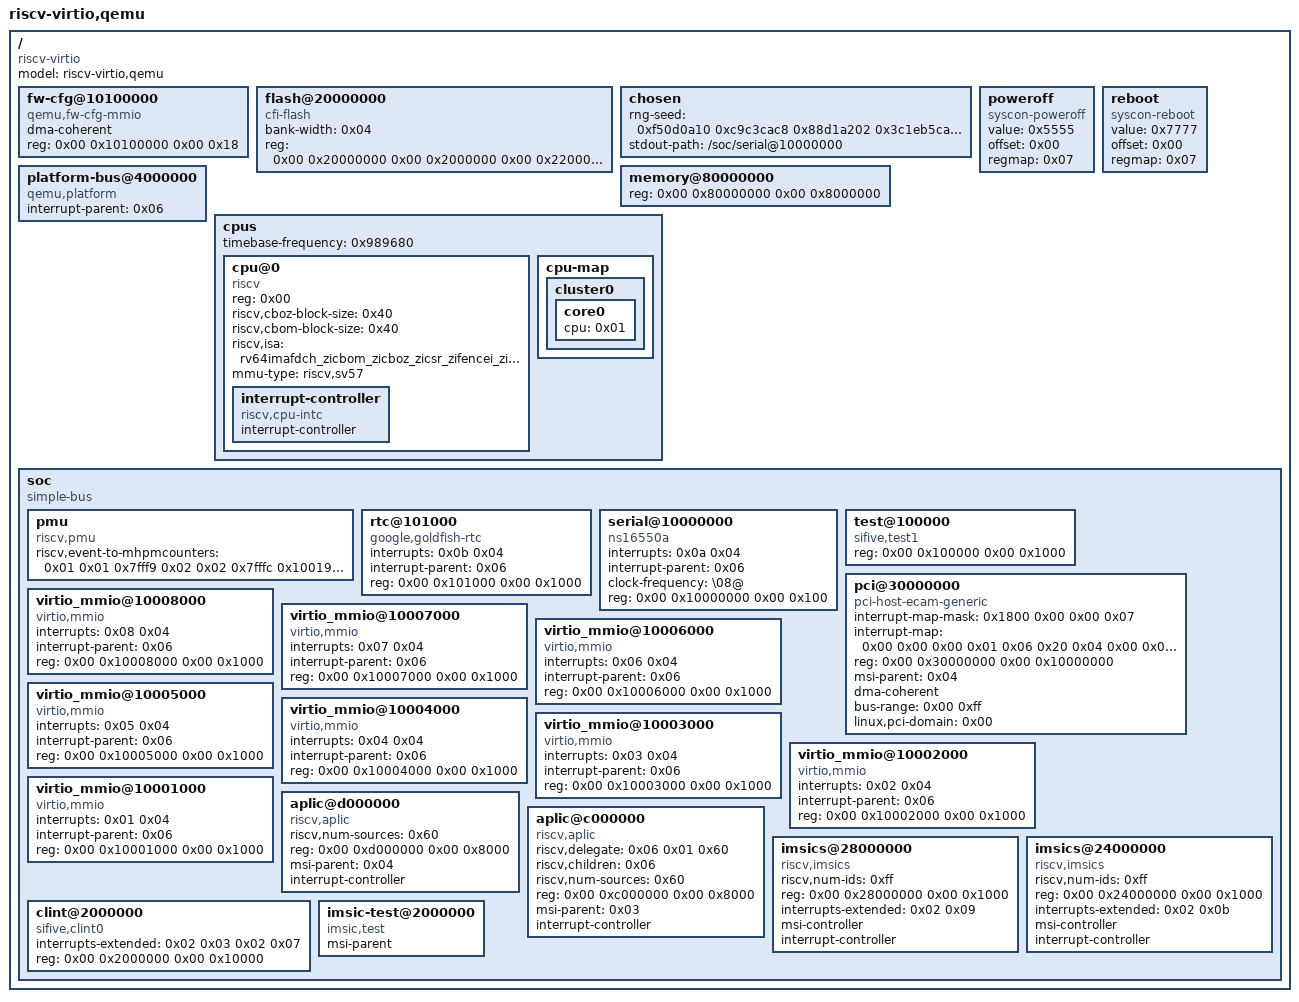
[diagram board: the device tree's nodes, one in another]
/dts-v1/;

/ {
	#address-cells = <0x02>;
	#size-cells = <0x02>;
	compatible = "riscv-virtio";
	model = "riscv-virtio,qemu";

	fw-cfg@10100000 {
		dma-coherent;
		reg = <0x00 0x10100000 0x00 0x18>;
		compatible = "qemu,fw-cfg-mmio";
	};

	flash@20000000 {
		bank-width = <0x04>;
		reg = <0x00 0x20000000 0x00 0x2000000 0x00 0x22000000 0x00 0x2000000>;
		compatible = "cfi-flash";
	};

	chosen {
		rng-seed = <0xf50d0a10 0xc9c3cac8 0x88d1a202 0x3c1eb5ca 0x6d25b5b9 0x8b1cad55 0xbd0cc887 0x8aa1972>;
		stdout-path = "/soc/serial@10000000";
	};

	poweroff {
		value = <0x5555>;
		offset = <0x00>;
		regmap = <0x07>;
		compatible = "syscon-poweroff";
	};

	reboot {
		value = <0x7777>;
		offset = <0x00>;
		regmap = <0x07>;
		compatible = "syscon-reboot";
	};

	platform-bus@4000000 {
		interrupt-parent = <0x06>;
		ranges = <0x00 0x00 0x4000000 0x2000000>;
		#address-cells = <0x01>;
		#size-cells = <0x01>;
		compatible = "qemu,platform\0simple-bus";
	};

	memory@80000000 {
		device_type = "memory";
		reg = <0x00 0x80000000 0x00 0x8000000>;
	};

	cpus {
		#address-cells = <0x01>;
		#size-cells = <0x00>;
		timebase-frequency = <0x989680>;

		cpu@0 {
			phandle = <0x01>;
			device_type = "cpu";
			reg = <0x00>;
			status = "okay";
			compatible = "riscv";
			riscv,cboz-block-size = <0x40>;
			riscv,cbom-block-size = <0x40>;
			riscv,isa = "rv64imafdch_zicbom_zicboz_zicsr_zifencei_zihintpause_zawrs_zfa_zca_zcd_zba_zbb_zbc_zbs_smaia_ssaia_sstc_svadu";
			mmu-type = "riscv,sv57";

			interrupt-controller {
				#interrupt-cells = <0x01>;
				interrupt-controller;
				compatible = "riscv,cpu-intc";
				phandle = <0x02>;
			};
		};

		cpu-map {

			cluster0 {

				core0 {
					cpu = <0x01>;
				};
			};
		};
	};

	soc {
		#address-cells = <0x02>;
		#size-cells = <0x02>;
		compatible = "simple-bus";
		ranges;

		pmu {
			riscv,event-to-mhpmcounters = <0x01 0x01 0x7fff9 0x02 0x02 0x7fffc 0x10019 0x10019 0x7fff8 0x1001b 0x1001b 0x7fff8 0x10021 0x10021 0x7fff8>;
			compatible = "riscv,pmu";
		};

		rtc@101000 {
			interrupts = <0x0b 0x04>;
			interrupt-parent = <0x06>;
			reg = <0x00 0x101000 0x00 0x1000>;
			compatible = "google,goldfish-rtc";
		};

		serial@10000000 {
			interrupts = <0x0a 0x04>;
			interrupt-parent = <0x06>;
			clock-frequency = "\08@";
			reg = <0x00 0x10000000 0x00 0x100>;
			compatible = "ns16550a";
		};

		test@100000 {
			phandle = <0x07>;
			reg = <0x00 0x100000 0x00 0x1000>;
			compatible = "sifive,test1\0sifive,test0\0syscon";
		};

		pci@30000000 {
			interrupt-map-mask = <0x1800 0x00 0x00 0x07>;
			interrupt-map = <0x00 0x00 0x00 0x01 0x06 0x20 0x04 0x00 0x00 0x00 0x02 0x06 0x21 0x04 0x00 0x00 0x00 0x03 0x06 0x22 0x04 0x00 0x00 0x00 0x04 0x06 0x23 0x04 0x800 0x00 0x00 0x01 0x06 0x21 0x04 0x800 0x00 0x00 0x02 0x06 0x22 0x04 0x800 0x00 0x00 0x03 0x06 0x23 0x04 0x800 0x00 0x00 0x04 0x06 0x20 0x04 0x1000 0x00 0x00 0x01 0x06 0x22 0x04 0x1000 0x00 0x00 0x02 0x06 0x23 0x04 0x1000 0x00 0x00 0x03 0x06 0x20 0x04 0x1000 0x00 0x00 0x04 0x06 0x21 0x04 0x1800 0x00 0x00 0x01 0x06 0x23 0x04 0x1800 0x00 0x00 0x02 0x06 0x20 0x04 0x1800 0x00 0x00 0x03 0x06 0x21 0x04 0x1800 0x00 0x00 0x04 0x06 0x22 0x04>;
			ranges = <0x1000000 0x00 0x00 0x00 0x3000000 0x00 0x10000 0x2000000 0x00 0x40000000 0x00 0x40000000 0x00 0x40000000 0x3000000 0x04 0x00 0x04 0x00 0x04 0x00>;
			reg = <0x00 0x30000000 0x00 0x10000000>;
			msi-parent = <0x04>;
			dma-coherent;
			bus-range = <0x00 0xff>;
			linux,pci-domain = <0x00>;
			device_type = "pci";
			compatible = "pci-host-ecam-generic";
			#size-cells = <0x02>;
			#interrupt-cells = <0x01>;
			#address-cells = <0x03>;
		};

		virtio_mmio@10008000 {
			interrupts = <0x08 0x04>;
			interrupt-parent = <0x06>;
			reg = <0x00 0x10008000 0x00 0x1000>;
			compatible = "virtio,mmio";
		};

		virtio_mmio@10007000 {
			interrupts = <0x07 0x04>;
			interrupt-parent = <0x06>;
			reg = <0x00 0x10007000 0x00 0x1000>;
			compatible = "virtio,mmio";
		};

		virtio_mmio@10006000 {
			interrupts = <0x06 0x04>;
			interrupt-parent = <0x06>;
			reg = <0x00 0x10006000 0x00 0x1000>;
			compatible = "virtio,mmio";
		};

		virtio_mmio@10005000 {
			interrupts = <0x05 0x04>;
			interrupt-parent = <0x06>;
			reg = <0x00 0x10005000 0x00 0x1000>;
			compatible = "virtio,mmio";
		};

		virtio_mmio@10004000 {
			interrupts = <0x04 0x04>;
			interrupt-parent = <0x06>;
			reg = <0x00 0x10004000 0x00 0x1000>;
			compatible = "virtio,mmio";
		};

		virtio_mmio@10003000 {
			interrupts = <0x03 0x04>;
			interrupt-parent = <0x06>;
			reg = <0x00 0x10003000 0x00 0x1000>;
			compatible = "virtio,mmio";
		};

		virtio_mmio@10002000 {
			interrupts = <0x02 0x04>;
			interrupt-parent = <0x06>;
			reg = <0x00 0x10002000 0x00 0x1000>;
			compatible = "virtio,mmio";
		};

		virtio_mmio@10001000 {
			interrupts = <0x01 0x04>;
			interrupt-parent = <0x06>;
			reg = <0x00 0x10001000 0x00 0x1000>;
			compatible = "virtio,mmio";
		};

		aplic@d000000 {
			phandle = <0x06>;
			riscv,num-sources = <0x60>;
			reg = <0x00 0xd000000 0x00 0x8000>;
			msi-parent = <0x04>;
			interrupt-controller;
			#interrupt-cells = <0x02>;
			compatible = "riscv,aplic";
		};

		aplic@c000000 {
			phandle = <0x05>;
			riscv,delegate = <0x06 0x01 0x60>;
			riscv,children = <0x06>;
			riscv,num-sources = <0x60>;
			reg = <0x00 0xc000000 0x00 0x8000>;
			msi-parent = <0x03>;
			interrupt-controller;
			#interrupt-cells = <0x02>;
			compatible = "riscv,aplic";
		};

		imsics@28000000 {
			phandle = <0x04>;
			riscv,num-ids = <0xff>;
			reg = <0x00 0x28000000 0x00 0x1000>;
			interrupts-extended = <0x02 0x09>;
			msi-controller;
			interrupt-controller;
			#interrupt-cells = <0x00>;
			compatible = "riscv,imsics";
		};

		imsics@24000000 {
			phandle = <0x03>;
			riscv,num-ids = <0xff>;
			reg = <0x00 0x24000000 0x00 0x1000>;
			interrupts-extended = <0x02 0x0b>;
			msi-controller;
			interrupt-controller;
			#interrupt-cells = <0x00>;
			compatible = "riscv,imsics";
		};

		clint@2000000 {
			interrupts-extended = <0x02 0x03 0x02 0x07>;
			reg = <0x00 0x2000000 0x00 0x10000>;
			compatible = "sifive,clint0\0riscv,clint0";
		};

		imsic-test@2000000 {
			compatible = "imsic,test";
			msi-parent;
		};
	};
};
